AUTOSAR XML (schema 4-2-2)
package /Components
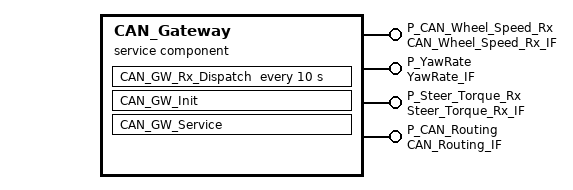
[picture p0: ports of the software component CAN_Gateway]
  service sw component type CAN_Gateway
    4 x provide port:
      P_CAN_Wheel_Speed_Rx: provided-interface=CAN_Wheel_Speed_Rx_IF
      P_YawRate: provided-interface=YawRate_IF
      P_Steer_Torque_Rx: provided-interface=Steer_Torque_Rx_IF
      P_CAN_Routing: provided-interface=CAN_Routing_IF
    behavior CAN_Gateway_InternalBehavior
      init event CAN_GW_Init_Event: start-on-event=CAN_GW_Init
      operation invoked event CAN_GW_Service_Invoke: start-on-event=CAN_GW_Service
      timing event CAN_GW_Rx_Event: start-on-event=CAN_GW_Rx_Dispatch, period=10
      runnable CAN_GW_Init
        data-send-points:
          6 x access:
            VA_Init_RawWS_FL: accessed-variable=P_CAN_Wheel_Speed_Rx.raw_wheel_speed_fl
            VA_Init_RawWS_FR: accessed-variable=P_CAN_Wheel_Speed_Rx.raw_wheel_speed_fr
            VA_Init_RawWS_RL: accessed-variable=P_CAN_Wheel_Speed_Rx.raw_wheel_speed_rl
            VA_Init_RawWS_RR: accessed-variable=P_CAN_Wheel_Speed_Rx.raw_wheel_speed_rr
            VA_Init_YawRate: accessed-variable=P_YawRate.yaw_rate
            VA_Init_SteerTorque: accessed-variable=P_Steer_Torque_Rx.steer_torque
      runnable CAN_GW_Rx_Dispatch: minimum-start-interval=10
        data-send-points:
          6 x access:
            VA_Rx_RawWS_FL: accessed-variable=P_CAN_Wheel_Speed_Rx.raw_wheel_speed_fl
            VA_Rx_RawWS_FR: accessed-variable=P_CAN_Wheel_Speed_Rx.raw_wheel_speed_fr
            VA_Rx_RawWS_RL: accessed-variable=P_CAN_Wheel_Speed_Rx.raw_wheel_speed_rl
            VA_Rx_RawWS_RR: accessed-variable=P_CAN_Wheel_Speed_Rx.raw_wheel_speed_rr
            VA_Rx_YawRate: accessed-variable=P_YawRate.yaw_rate
            VA_Rx_SteerTorque: accessed-variable=P_Steer_Torque_Rx.steer_torque
      runnable CAN_GW_Service
        data-send-points:
          access VA_Service_YawRate_Feedback: accessed-variable=P_YawRate.yaw_rate
          access VA_Service_SteerTorque_Feedback: accessed-variable=P_Steer_Torque_Rx.steer_torque
